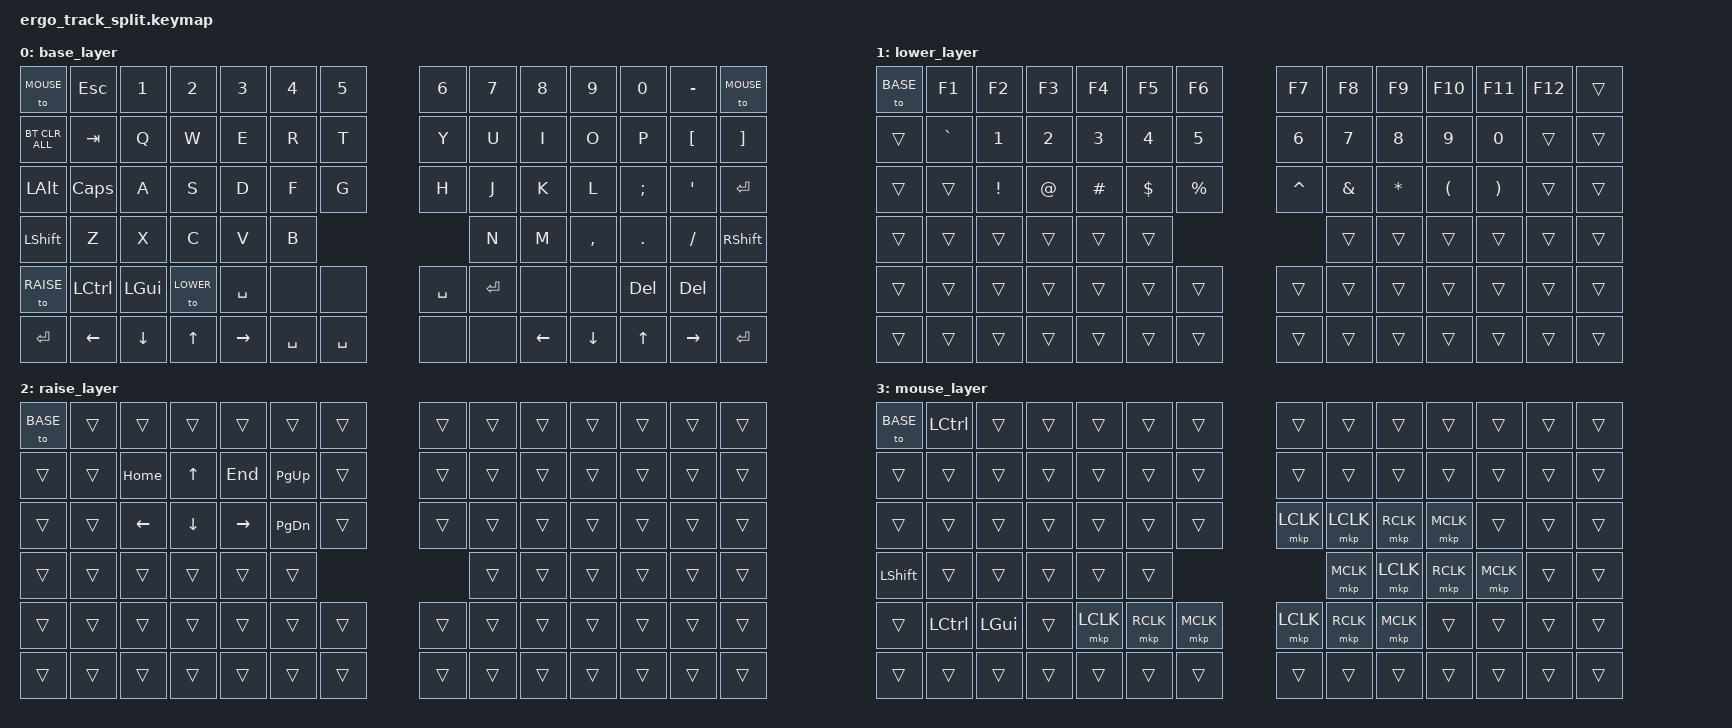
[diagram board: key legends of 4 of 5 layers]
/*
 * SPDX-License-Identifier: MIT
 */

#include <behaviors.dtsi>
#include <dt-bindings/zmk/keys.h>
#include <dt-bindings/zmk/bt.h>
#include <dt-bindings/zmk/mouse.h>
#include <dt-bindings/zmk/outputs.h>

#define BASE  0
#define LOWER 1
#define RAISE 2
#define MOUSE 3
#define FUNC  4

/ {
    conditional_layers {
        compatible = "zmk,conditional-layers";
        func_layer {
            if-layers = <LOWER RAISE>;
            then-layer = <FUNC>;
        };
    };

    keymap {
        compatible = "zmk,keymap";

        // ==================== BASE LAYER ====================
        base_layer {
            bindings = <
            &to MOUSE &kp ESC &kp N1 &kp N2 &kp N3 &kp N4 &kp N5     &kp N6 &kp N7 &kp N8 &kp N9 &kp N0 &kp MINUS &to MOUSE
            &bt BT_CLR_ALL &kp TAB &kp Q &kp W &kp E &kp R &kp T    &kp Y &kp U &kp I &kp O &kp P &kp LBKT &kp RBKT
            &kp LALT &kp CAPS &kp A &kp S &kp D &kp F &kp G         &kp H &kp J &kp K &kp L &kp SEMI &kp APOS &kp RET
                     &kp LSHFT &kp Z &kp X &kp C &kp V &kp B        &kp N &kp M &kp COMMA &kp DOT &kp FSLH &kp RSHFT
            &to RAISE &kp LCTRL &kp LGUI &to LOWER &kp SPACE &none &none    &kp SPACE &kp RET &none &none &kp DEL &kp DEL &none
            &kp RET &kp LEFT &kp DOWN &kp UP &kp RIGHT &kp SPACE &kp SPACE  &none &none &kp LEFT &kp DOWN &kp UP &kp RIGHT &kp RET
            >;
            sensor-bindings = <&inc_dec_kp C_VOL_UP C_VOL_DN &inc_dec_kp PG_UP PG_DN &inc_dec_kp C_VOL_UP C_VOL_DN>;
        };

        // ==================== LOWER LAYER ====================
        lower_layer {
            bindings = <
            &to BASE &kp F1 &kp F2 &kp F3 &kp F4 &kp F5 &kp F6      &kp F7 &kp F8 &kp F9 &kp F10 &kp F11 &kp F12 &trans
            &trans &kp GRAVE &kp N1 &kp N2 &kp N3 &kp N4 &kp N5     &kp N6 &kp N7 &kp N8 &kp N9 &kp N0 &trans &trans
            &trans &trans &kp EXCL &kp AT &kp HASH &kp DLLR &kp PRCNT   &kp CARET &kp AMPS &kp STAR &kp LPAR &kp RPAR &trans &trans
                   &trans &trans &trans &trans &trans &trans        &trans &trans &trans &trans &trans &trans
            &trans &trans &trans &trans &trans &trans &trans        &trans &trans &trans &trans &trans &trans &trans
            &trans &trans &trans &trans &trans &trans &trans        &trans &trans &trans &trans &trans &trans &trans
            >;
            sensor-bindings = <&inc_dec_kp C_BRI_UP C_BRI_DN &inc_dec_kp PG_UP PG_DN &inc_dec_kp C_BRI_UP C_BRI_DN>;
        };

        // ==================== RAISE LAYER ====================
        raise_layer {
            bindings = <
            &to BASE &trans &trans &trans &trans &trans &trans      &trans &trans &trans &trans &trans &trans &trans
            &trans &trans &kp HOME &kp UP &kp END &kp PG_UP &trans  &trans &trans &trans &trans &trans &trans &trans
            &trans &trans &kp LEFT &kp DOWN &kp RIGHT &kp PG_DN &trans  &trans &trans &trans &trans &trans &trans &trans
                   &trans &trans &trans &trans &trans &trans        &trans &trans &trans &trans &trans &trans
            &trans &trans &trans &trans &trans &trans &trans        &trans &trans &trans &trans &trans &trans &trans
            &trans &trans &trans &trans &trans &trans &trans        &trans &trans &trans &trans &trans &trans &trans
            >;
            sensor-bindings = <&inc_dec_kp C_VOL_UP C_VOL_DN &inc_dec_kp UP DOWN &inc_dec_kp C_VOL_UP C_VOL_DN>;
        };

        // ==================== MOUSE LAYER ====================
        mouse_layer {
            bindings = <
            &to BASE &kp LCTRL &trans &trans &trans &trans &trans   &trans &trans &trans &trans &trans &trans &trans
            &trans &trans &trans &trans &trans &trans &trans        &trans &trans &trans &trans &trans &trans &trans
            &trans &trans &trans &trans &trans &trans &trans        &mkp LCLK &mkp LCLK &mkp RCLK &mkp MCLK &trans &trans &trans
                   &kp LSHFT &trans &trans &trans &trans &trans     &mkp MCLK &mkp LCLK &mkp RCLK &mkp MCLK &trans &trans
            &trans &kp LCTRL &kp LGUI &trans &mkp LCLK &mkp RCLK &mkp MCLK  &mkp LCLK &mkp RCLK &mkp MCLK &trans &trans &trans &trans
            &trans &trans &trans &trans &trans &trans &trans        &trans &trans &trans &trans &trans &trans &trans
            >;
            sensor-bindings = <&inc_dec_kp C_VOL_UP C_VOL_DN &inc_dec_kp C_AC_SCROLL_UP C_AC_SCROLL_DOWN &inc_dec_kp C_AC_SCROLL_UP C_AC_SCROLL_DOWN>;
        };

        // ==================== FUNCTION LAYER ====================
        function_layer {
            bindings = <
            &bt BT_CLR_ALL &bt BT_SEL 0 &bt BT_SEL 1 &bt BT_SEL 2 &bt BT_SEL 3 &bt BT_SEL 4 &out OUT_TOG
            &trans &trans &trans &trans &trans &trans &bootloader
            &out OUT_BLE &trans &trans &trans &trans &trans &trans
            &trans &trans &trans &trans &trans &trans &trans
            &out OUT_USB &trans &trans &trans &trans &trans &trans
            &trans &trans &trans &trans &trans &trans &trans
            &trans &trans &trans &trans &trans &trans &trans
            &trans &bt BT_PRV &trans &trans &bt BT_NXT &trans &trans
            &trans &trans &trans &trans &trans &trans &trans
            >;
            sensor-bindings = <&inc_dec_kp BT_NXT BT_PRV &inc_dec_kp BT_NXT BT_PRV &inc_dec_kp BT_NXT BT_PRV>;
        };
    };
};
